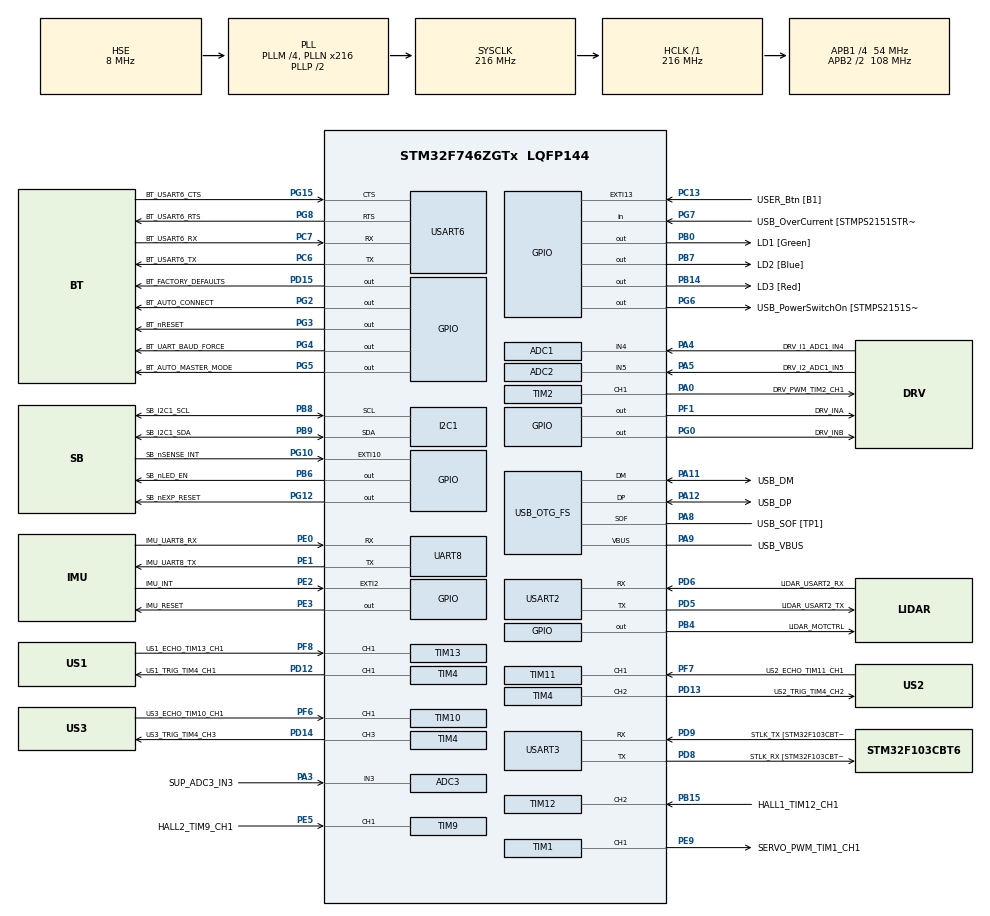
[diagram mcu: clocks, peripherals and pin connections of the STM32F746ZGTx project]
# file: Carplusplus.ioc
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ADC1.Channel-0\#ChannelRegularConversion=ADC_CHANNEL_4
ADC1.ContinuousConvMode=DISABLE
ADC1.EOCSelection=ADC_EOC_SINGLE_CONV
ADC1.NbrOfConversion=1
ADC1.NbrOfConversionFlag=1
ADC1.Rank-0\#ChannelRegularConversion=1
ADC1.SamplingTime-0\#ChannelRegularConversion=ADC_SAMPLETIME_480CYCLES
ADC1.ScanConvMode=DISABLE
ADC1.master=1
ADC2.Channel-3\#ChannelRegularConversion=ADC_CHANNEL_5
ADC2.NbrOfConversionFlag=1
ADC2.Rank-3\#ChannelRegularConversion=1
ADC2.SamplingTime-3\#ChannelRegularConversion=ADC_SAMPLETIME_3CYCLES
ADC3.Channel-0\#ChannelRegularConversion=ADC_CHANNEL_3
ADC3.NbrOfConversionFlag=1
ADC3.Rank-0\#ChannelRegularConversion=1
ADC3.SamplingTime-0\#ChannelRegularConversion=ADC_SAMPLETIME_3CYCLES
FREERTOS.Tasks01=defaultTask,0,256,StartDefaultTask,Default,NULL,Dynamic,NULL,NULL
I2C1.Timing=0x20404768
Mcu.Family=STM32F7
Mcu.Name=STM32F746ZGTx
Mcu.Package=LQFP144
NVIC.PriorityGroup=NVIC_PRIORITYGROUP_4
NVIC.TIM8_TRG_COM_TIM14_IRQn=true\:0\:0\:false\:false\:true\:false\:false\:true
NVIC.TimeBase=TIM8_TRG_COM_TIM14_IRQn
NVIC.TimeBaseIP=TIM14
NVIC.UART8_IRQn=true\:5\:0\:false\:false\:true\:true\:true\:true
PA0/WKUP.GPIO_Label=DRV_PWM_TIM2_CH1
PA0/WKUP.Signal=S_TIM2_CH1_ETR
PA10.GPIO_Label=USB_ID
PA10.Signal=USB_OTG_FS_ID
PA11.GPIO_Label=USB_DM
PA11.Mode=Device_Only
PA11.Signal=USB_OTG_FS_DM
PA12.GPIO_Label=USB_DP
PA12.Mode=Device_Only
PA12.Signal=USB_OTG_FS_DP
PA13.GPIO_Label=TMS
PA13.Mode=Serial_Wire
PA13.Signal=SYS_JTMS-SWDIO
PA14.GPIO_Label=TCK
PA14.Mode=Serial_Wire
PA14.Signal=SYS_JTCK-SWCLK
PA3.GPIO_Label=SUP_ADC3_IN3
PA3.Signal=ADCx_IN3
PA4.GPIO_Label=DRV_I1_ADC1_IN4
PA4.Signal=ADCx_IN4
PA5.GPIO_Label=DRV_I2_ADC1_IN5
PA5.Signal=ADCx_IN5
PA8.GPIO_Label=USB_SOF [TP1]
PA8.Mode=Activate_SOF_FS
PA8.Signal=USB_OTG_FS_SOF
PA9.GPIO_Label=USB_VBUS
PA9.Mode=Activate_VBUS
PA9.Signal=USB_OTG_FS_VBUS
PB0.GPIO_Label=LD1 [Green]
PB0.Signal=GPIO_Output
PB14.GPIO_Label=LD3 [Red]
PB14.Signal=GPIO_Output
PB15.GPIO_Label=HALL1_TIM12_CH1
PB15.Signal=S_TIM12_CH2
PB3.GPIO_Label=SW0
PB3.Signal=SYS_JTDO-SWO
PB4.GPIO_Label=LIDAR_MOTCTRL
PB4.Signal=GPIO_Output
PB6.GPIO_Label=SB_nLED_EN
PB6.GPIO_ModeDefaultOutputPP=GPIO_MODE_OUTPUT_OD
PB6.PinState=GPIO_PIN_SET
PB6.Signal=GPIO_Output
PB7.GPIO_Label=LD2 [Blue]
PB7.Signal=GPIO_Output
PB8.GPIO_Label=SB_I2C1_SCL
PB8.Mode=I2C
PB8.Signal=I2C1_SCL
PB9.GPIO_Label=SB_I2C1_SDA
PB9.Mode=I2C
PB9.Signal=I2C1_SDA
PC13.GPIO_Label=USER_Btn [B1]
PC13.Signal=GPXTI13
PC14/OSC32_IN.Mode=LSE-External-Oscillator
PC14/OSC32_IN.Signal=RCC_OSC32_IN
PC15/OSC32_OUT.Mode=LSE-External-Oscillator
PC15/OSC32_OUT.Signal=RCC_OSC32_OUT
PC6.GPIO_Label=BT_USART6_TX
PC6.Mode=Asynchronous
PC6.Signal=USART6_TX
PC7.GPIO_Label=BT_USART6_RX
PC7.Mode=Asynchronous
PC7.Signal=USART6_RX
PD12.GPIO_Label=US1_TRIG_TIM4_CH1
PD12.Signal=S_TIM4_CH1
PD13.GPIO_Label=US2_TRIG_TIM4_CH2
PD13.Signal=S_TIM4_CH2
PD14.GPIO_Label=US3_TRIG_TIM4_CH3
PD14.Signal=S_TIM4_CH3
PD15.GPIO_Label=BT_FACTORY_DEFAULTS
PD15.Signal=GPIO_Output
PD5.GPIO_Label=LIDAR_USART2_TX
PD5.Mode=Asynchronous
PD5.Signal=USART2_TX
PD6.GPIO_Label=LIDAR_USART2_RX
PD6.Mode=Asynchronous
PD6.Signal=USART2_RX
PD8.GPIO_Label=STLK_RX [STM32F103CBT6_PA3]
PD8.Mode=Asynchronous
PD8.Signal=USART3_TX
PD9.GPIO_Label=STLK_TX [STM32F103CBT6_PA2]
PD9.Mode=Asynchronous
PD9.Signal=USART3_RX
PE0.GPIO_Label=IMU_UART8_RX
PE0.Mode=Asynchronous
PE0.Signal=UART8_RX
PE1.GPIO_Label=IMU_UART8_TX
PE1.Mode=Asynchronous
PE1.Signal=UART8_TX
PE2.GPIO_Label=IMU_INT
PE2.Signal=GPXTI2
PE3.GPIO_Label=IMU_RESET
PE3.Signal=GPIO_Output
PE5.GPIO_Label=HALL2_TIM9_CH1
PE5.Signal=S_TIM9_CH1
PE9.GPIO_Label=SERVO_PWM_TIM1_CH1
PE9.Signal=S_TIM1_CH1
PF1.GPIO_Label=DRV_INA
PF1.Signal=GPIO_Output
PF6.GPIO_Label=US3_ECHO_TIM10_CH1
PF6.Signal=S_TIM10_CH1
PF7.GPIO_Label=US2_ECHO_TIM11_CH1
PF7.Signal=S_TIM11_CH1
PF8.GPIO_Label=US1_ECHO_TIM13_CH1
PF8.Signal=S_TIM13_CH1
PG0.GPIO_Label=DRV_INB
PG0.Signal=GPIO_Output
PG10.GPIO_Label=SB_nSENSE_INT
PG10.Signal=GPXTI10
PG12.GPIO_Label=SB_nEXP_RESET
PG12.Signal=GPIO_Output
PG15.GPIO_Label=BT_USART6_CTS
PG15.Mode=CTS_RTS
PG15.Signal=USART6_CTS
PG2.GPIO_Label=BT_AUTO_CONNECT
PG2.Signal=GPIO_Output
PG3.GPIO_Label=BT_nRESET
PG3.Signal=GPIO_Output
PG4.GPIO_Label=BT_UART_BAUD_FORCE
PG4.Signal=GPIO_Output
PG5.GPIO_Label=BT_AUTO_MASTER_MODE
PG5.Signal=GPIO_Output
PG6.GPIO_Label=USB_PowerSwitchOn [STMPS2151STR_EN]
PG6.Signal=GPIO_Output
PG7.GPIO_Label=USB_OverCurrent [STMPS2151STR_FAULT]
PG7.Signal=GPIO_Input
PG8.GPIO_Label=BT_USART6_RTS
PG8.Mode=CTS_RTS
PG8.Signal=USART6_RTS
PH0/OSC_IN.GPIO_Label=MCO [STM32F103CBT6_PA8]
PH0/OSC_IN.Mode=HSE-External-Clock-Source
PH0/OSC_IN.Signal=RCC_OSC_IN
PH1/OSC_OUT.Mode=HSE-External-Clock-Source
PH1/OSC_OUT.Signal=RCC_OSC_OUT
ProjectManager.HeapSize=0x200
ProjectManager.StackSize=0x400
ProjectManager.TargetToolchain=SW4STM32
RCC.48MHZClocksFreq_Value=24000000
RCC.AHBFreq_Value=216000000
RCC.APB1CLKDivider=RCC_HCLK_DIV4
RCC.APB1Freq_Value=54000000
RCC.APB1TimFreq_Value=108000000
RCC.APB2CLKDivider=RCC_HCLK_DIV2
RCC.APB2Freq_Value=108000000
RCC.APB2TimFreq_Value=216000000
RCC.CortexFreq_Value=216000000
RCC.HCLKFreq_Value=216000000
RCC.HSE_VALUE=8000000
RCC.HSI_VALUE=16000000
RCC.PLLM=4
RCC.PLLMUL=RCC_PLL_MUL9
RCC.PLLN=216
RCC.PLLQ=9
RCC.PRESCALERUSB=RCC_USBCLKSOURCE_PLL_DIV1_5
RCC.SYSCLKFreq_VALUE=216000000
RCC.SYSCLKSource=RCC_SYSCLKSOURCE_PLLCLK
RCC.SYSCLKSourceVirtual=RCC_SYSCLKSOURCE_PLLCLK
RCC.USBFreq_Value=48000000
RCC.VCOOutputFreq_Value=432000000
SH.ADCx_IN3.0=ADC3_IN3,IN3
SH.ADCx_IN4.0=ADC1_IN4,IN4
SH.ADCx_IN5.0=ADC2_IN5,IN5
SH.S_TIM10_CH1.0=TIM10_CH1,Input_Capture1_from_TI1
SH.S_TIM11_CH1.0=TIM11_CH1,Input_Capture1_from_TI1
SH.S_TIM12_CH2.0=TIM12_CH2,Input_Capture2_from_TI2
SH.S_TIM13_CH1.0=TIM13_CH1,Input_Capture1_from_TI1
SH.S_TIM1_CH1.0=TIM1_CH1,PWM Generation1 CH1
SH.S_TIM2_CH1_ETR.0=TIM2_CH1,PWM Generation1 CH1
SH.S_TIM4_CH1.0=TIM4_CH1,PWM Generation1 CH1
SH.S_TIM4_CH2.0=TIM4_CH2,PWM Generation2 CH2
SH.S_TIM4_CH3.0=TIM4_CH3,PWM Generation3 CH3
SH.S_TIM9_CH1.0=TIM9_CH1,Input_Capture1_from_TI1
TIM1.Channel-PWM\ Generation1\ CH1=TIM_CHANNEL_1
TIM1.OCPolarity_1=TIM_OCPOLARITY_LOW
TIM1.Period=10000
TIM1.Prescaler=108
TIM10.Channel=TIM_CHANNEL_1
TIM11.Channel=TIM_CHANNEL_1
TIM12.Channel-Input_Capture2_from_TI2=TIM_CHANNEL_2
TIM13.Channel=TIM_CHANNEL_1
TIM2.Channel-PWM\ Generation1\ CH1=TIM_CHANNEL_1
TIM2.Period=10800
TIM4.Channel-PWM\ Generation1\ CH1=TIM_CHANNEL_1
TIM4.Channel-PWM\ Generation2\ CH2=TIM_CHANNEL_2
TIM4.Channel-PWM\ Generation3\ CH3=TIM_CHANNEL_3
TIM9.Channel-Input_Capture1_from_TI1=TIM_CHANNEL_1
USART2.VirtualMode-Asynchronous=VM_ASYNC
USART3.VirtualMode-Asynchronous=VM_ASYNC
USART6.VirtualMode-Asynchronous=VM_ASYNC
USB_OTG_FS.VirtualMode=Device_Only
VP_FREERTOS_VS_CMSIS_V1.Mode=CMSIS_V1
VP_SYS_VS_tim14.Mode=TIM14
VP_TIM10_VS_ClockSourceINT.Mode=Enable_Timer
VP_TIM11_VS_ClockSourceINT.Mode=Enable_Timer
VP_TIM13_VS_ClockSourceINT.Mode=Enable_Timer
board=NUCLEO-F746ZG

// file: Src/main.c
/* USER CODE BEGIN Header */
/**
  ******************************************************************************
  * @file           : main.c
  * @brief          : Main program body
  ******************************************************************************
  * This notice applies to any and all portions of this file
  * that are not between comment pairs USER CODE BEGIN and
  * USER CODE END. Other portions of this file, whether
  * inserted by the user or by software development tools
  * are owned by their respective copyright owners.
  *
  * Copyright (c) 2019 STMicroelectronics International N.V.
  * All rights reserved.
  *
  * Redistribution and use in source and binary forms, with or without
  * modification, are permitted, provided that the following conditions are met:
  *
  * 1. Redistribution of source code must retain the above copyright notice,
  *    this list of conditions and the following disclaimer.
  * 2. Redistributions in binary form must reproduce the above copyright notice,
  *    this list of conditions and the following disclaimer in the documentation
  *    and/or other materials provided with the distribution.
  * 3. Neither the name of STMicroelectronics nor the names of other
  *    contributors to this software may be used to endorse or promote products
  *    derived from this software without specific written permission.
  * 4. This software, including modifications and/or derivative works of this
  *    software, must execute solely and exclusively on microcontroller or
  *    microprocessor devices manufactured by or for STMicroelectronics.
  * 5. Redistribution and use of this software other than as permitted under
  *    this license is void and will automatically terminate your rights under
  *    this license.
  *
  * THIS SOFTWARE IS PROVIDED BY STMICROELECTRONICS AND CONTRIBUTORS "AS IS"
  * AND ANY EXPRESS, IMPLIED OR STATUTORY WARRANTIES, INCLUDING, BUT NOT
  * LIMITED TO, THE IMPLIED WARRANTIES OF MERCHANTABILITY, FITNESS FOR A
  * PARTICULAR PURPOSE AND NON-INFRINGEMENT OF THIRD PARTY INTELLECTUAL PROPERTY
  * RIGHTS ARE DISCLAIMED TO THE FULLEST EXTENT PERMITTED BY LAW. IN NO EVENT
  * SHALL STMICROELECTRONICS OR CONTRIBUTORS BE LIABLE FOR ANY DIRECT, INDIRECT,
  * INCIDENTAL, SPECIAL, EXEMPLARY, OR CONSEQUENTIAL DAMAGES (INCLUDING, BUT NOT
  * LIMITED TO, PROCUREMENT OF SUBSTITUTE GOODS OR SERVICES; LOSS OF USE, DATA,
  * OR PROFITS; OR BUSINESS INTERRUPTION) HOWEVER CAUSED AND ON ANY THEORY OF
  * LIABILITY, WHETHER IN CONTRACT, STRICT LIABILITY, OR TORT (INCLUDING
  * NEGLIGENCE OR OTHERWISE) ARISING IN ANY WAY OUT OF THE USE OF THIS SOFTWARE,
  * EVEN IF ADVISED OF THE POSSIBILITY OF SUCH DAMAGE.
  *
  ******************************************************************************
  */
/* USER CODE END Header */

#include "main.h"
#include "cmsis_os.h"
#include "adc.h"
#include "gfxsimulator.h"
#include "i2c.h"
#include "tim.h"
#include "usart.h"
#include "usb_otg.h"
#include "gpio.h"

void SystemClock_Config(void);
void MX_FREERTOS_Init(void);

int main(void)
{

  /* MCU Configuration--------------------------------------------------------*/

  /* Reset of all peripherals, Initializes the Flash interface and the Systick. */
  HAL_Init();

  /* Configure the system clock */
  SystemClock_Config();

  /* Initialize all configured peripherals */
  MX_GPIO_Init();
  MX_ADC1_Init();
  MX_ADC2_Init();
  MX_ADC3_Init();
  MX_I2C1_Init();
  MX_TIM1_Init();
  MX_TIM2_Init();
  MX_TIM4_Init();
  MX_TIM9_Init();
  MX_TIM10_Init();
  MX_TIM11_Init();
  MX_TIM12_Init();
  MX_TIM13_Init();
  MX_UART8_Init();
  MX_USART2_UART_Init();
  MX_USART3_UART_Init();
  MX_USART6_UART_Init();
  MX_GFXSIMULATOR_Init();

  /* Call init function for freertos objects (in freertos.c) */
  MX_FREERTOS_Init();

  /* Start scheduler */
  osKernelStart();

  /* We should never get here as control is now taken by the scheduler */

  /* Infinite loop */
  while (1)
  {

  }
}

void SystemClock_Config(void)
{
  RCC_OscInitTypeDef RCC_OscInitStruct = {0};
  RCC_ClkInitTypeDef RCC_ClkInitStruct = {0};
  RCC_PeriphCLKInitTypeDef PeriphClkInitStruct = {0};

  /** Configure LSE Drive Capability
  */
  HAL_PWR_EnableBkUpAccess();
  /** Configure the main internal regulator output voltage
  */
  __HAL_RCC_PWR_CLK_ENABLE();
  __HAL_PWR_VOLTAGESCALING_CONFIG(PWR_REGULATOR_VOLTAGE_SCALE1);
  /** Initializes the CPU, AHB and APB busses clocks
  */
  RCC_OscInitStruct.OscillatorType = RCC_OSCILLATORTYPE_HSI|RCC_OSCILLATORTYPE_HSE;
  RCC_OscInitStruct.HSEState = RCC_HSE_BYPASS;
  RCC_OscInitStruct.HSIState = RCC_HSI_ON;
  RCC_OscInitStruct.HSICalibrationValue = RCC_HSICALIBRATION_DEFAULT;
  RCC_OscInitStruct.PLL.PLLState = RCC_PLL_ON;
  RCC_OscInitStruct.PLL.PLLSource = RCC_PLLSOURCE_HSE;
  RCC_OscInitStruct.PLL.PLLM = 4;
  RCC_OscInitStruct.PLL.PLLN = 216;
  RCC_OscInitStruct.PLL.PLLP = RCC_PLLP_DIV2;
  RCC_OscInitStruct.PLL.PLLQ = 9;
  if (HAL_RCC_OscConfig(&RCC_OscInitStruct) != HAL_OK)
  {
    Error_Handler();
  }
  /** Activate the Over-Drive mode
  */
  if (HAL_PWREx_EnableOverDrive() != HAL_OK)
  {
    Error_Handler();
  }
  /** Initializes the CPU, AHB and APB busses clocks
  */
  RCC_ClkInitStruct.ClockType = RCC_CLOCKTYPE_HCLK|RCC_CLOCKTYPE_SYSCLK
                              |RCC_CLOCKTYPE_PCLK1|RCC_CLOCKTYPE_PCLK2;
  RCC_ClkInitStruct.SYSCLKSource = RCC_SYSCLKSOURCE_PLLCLK;
  RCC_ClkInitStruct.AHBCLKDivider = RCC_SYSCLK_DIV1;
  RCC_ClkInitStruct.APB1CLKDivider = RCC_HCLK_DIV4;
  RCC_ClkInitStruct.APB2CLKDivider = RCC_HCLK_DIV2;

  if (HAL_RCC_ClockConfig(&RCC_ClkInitStruct, FLASH_LATENCY_7) != HAL_OK)
  {
    Error_Handler();
  }
  PeriphClkInitStruct.PeriphClockSelection = RCC_PERIPHCLK_USART2|RCC_PERIPHCLK_USART3
                              |RCC_PERIPHCLK_USART6|RCC_PERIPHCLK_UART8
                              |RCC_PERIPHCLK_I2C1|RCC_PERIPHCLK_CLK48;
  PeriphClkInitStruct.Usart2ClockSelection = RCC_USART2CLKSOURCE_PCLK1;
  PeriphClkInitStruct.Usart3ClockSelection = RCC_USART3CLKSOURCE_PCLK1;
  PeriphClkInitStruct.Usart6ClockSelection = RCC_USART6CLKSOURCE_PCLK2;
  PeriphClkInitStruct.Uart8ClockSelection = RCC_UART8CLKSOURCE_PCLK1;
  PeriphClkInitStruct.I2c1ClockSelection = RCC_I2C1CLKSOURCE_PCLK1;
  PeriphClkInitStruct.Clk48ClockSelection = RCC_CLK48SOURCE_PLL;
  if (HAL_RCCEx_PeriphCLKConfig(&PeriphClkInitStruct) != HAL_OK)
  {
    Error_Handler();
  }
  HAL_RCC_MCOConfig(RCC_MCO1, RCC_MCO1SOURCE_HSI, RCC_MCODIV_1);
}

void HAL_TIM_PeriodElapsedCallback(TIM_HandleTypeDef *htim)
{
  if (htim->Instance == TIM14) {
    HAL_IncTick();
  }
}

void Error_Handler(void)
{
}

/************************ (C) COPYRIGHT STMicroelectronics *****END OF FILE****/

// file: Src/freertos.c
/* USER CODE BEGIN Header */
/**
  ******************************************************************************
  * File Name          : freertos.c
  * Description        : Code for freertos applications
  ******************************************************************************
  * This notice applies to any and all portions of this file
  * that are not between comment pairs USER CODE BEGIN and
  * USER CODE END. Other portions of this file, whether
  * inserted by the user or by software development tools
  * are owned by their respective copyright owners.
  *
  * Copyright (c) 2019 STMicroelectronics International N.V.
  * All rights reserved.
  *
  * Redistribution and use in source and binary forms, with or without
  * modification, are permitted, provided that the following conditions are met:
  *
  * 1. Redistribution of source code must retain the above copyright notice,
  *    this list of conditions and the following disclaimer.
  * 2. Redistributions in binary form must reproduce the above copyright notice,
  *    this list of conditions and the following disclaimer in the documentation
  *    and/or other materials provided with the distribution.
  * 3. Neither the name of STMicroelectronics nor the names of other
  *    contributors to this software may be used to endorse or promote products
  *    derived from this software without specific written permission.
  * 4. This software, including modifications and/or derivative works of this
  *    software, must execute solely and exclusively on microcontroller or
  *    microprocessor devices manufactured by or for STMicroelectronics.
  * 5. Redistribution and use of this software other than as permitted under
  *    this license is void and will automatically terminate your rights under
  *    this license.
  *
  * THIS SOFTWARE IS PROVIDED BY STMICROELECTRONICS AND CONTRIBUTORS "AS IS"
  * AND ANY EXPRESS, IMPLIED OR STATUTORY WARRANTIES, INCLUDING, BUT NOT
  * LIMITED TO, THE IMPLIED WARRANTIES OF MERCHANTABILITY, FITNESS FOR A
  * PARTICULAR PURPOSE AND NON-INFRINGEMENT OF THIRD PARTY INTELLECTUAL PROPERTY
  * RIGHTS ARE DISCLAIMED TO THE FULLEST EXTENT PERMITTED BY LAW. IN NO EVENT
  * SHALL STMICROELECTRONICS OR CONTRIBUTORS BE LIABLE FOR ANY DIRECT, INDIRECT,
  * INCIDENTAL, SPECIAL, EXEMPLARY, OR CONSEQUENTIAL DAMAGES (INCLUDING, BUT NOT
  * LIMITED TO, PROCUREMENT OF SUBSTITUTE GOODS OR SERVICES; LOSS OF USE, DATA,
  * OR PROFITS; OR BUSINESS INTERRUPTION) HOWEVER CAUSED AND ON ANY THEORY OF
  * LIABILITY, WHETHER IN CONTRACT, STRICT LIABILITY, OR TORT (INCLUDING
  * NEGLIGENCE OR OTHERWISE) ARISING IN ANY WAY OUT OF THE USE OF THIS SOFTWARE,
  * EVEN IF ADVISED OF THE POSSIBILITY OF SUCH DAMAGE.
  *
  ******************************************************************************
  */
/* USER CODE END Header */

#include "FreeRTOS.h"
#include "task.h"
#include "main.h"
#include "cmsis_os.h"

osThreadId defaultTaskHandle;

void StartDefaultTask(void const * argument);

void MX_FREERTOS_Init(void); /* (MISRA C 2004 rule 8.1) */

void MX_FREERTOS_Init(void) {

  /* Create the thread(s) */
  /* definition and creation of defaultTask */
  osThreadDef(defaultTask, StartDefaultTask, osPriorityNormal, 0, 256);
  defaultTaskHandle = osThreadCreate(osThread(defaultTask), NULL);

}

void StartDefaultTask(void const * argument)
{

  /* USER CODE BEGIN StartDefaultTask */
  /* Infinite loop */
  for(;;)
  {
    HAL_GPIO_TogglePin(LD1_GPIO_Port, LD1_Pin);
    osDelay(500);
  }
  /* USER CODE END StartDefaultTask */
}

/************************ (C) COPYRIGHT STMicroelectronics *****END OF FILE****/
